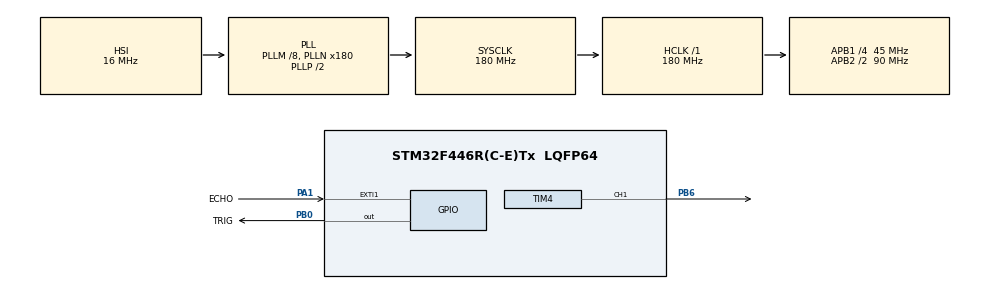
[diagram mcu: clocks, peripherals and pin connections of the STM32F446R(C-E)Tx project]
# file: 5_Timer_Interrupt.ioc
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Mcu.Family=STM32F4
Mcu.Name=STM32F446R(C-E)Tx
Mcu.Package=LQFP64
NVIC.EXTI1_IRQn=true\:0\:0\:false\:false\:true\:true\:true\:true
NVIC.PriorityGroup=NVIC_PRIORITYGROUP_4
NVIC.TIM6_DAC_IRQn=true\:0\:0\:false\:false\:true\:true\:true\:true
PA1.GPIO_Label=ECHO
PA1.GPIO_ModeDefaultEXTI=GPIO_MODE_IT_RISING_FALLING
PA1.Signal=GPXTI1
PB0.GPIO_Label=TRIG
PB0.Signal=GPIO_Output
PB6.Signal=S_TIM4_CH1
ProjectManager.HeapSize=0x200
ProjectManager.StackSize=0x400
ProjectManager.TargetToolchain=STM32CubeIDE
RCC.AHBFreq_Value=180000000
RCC.APB1CLKDivider=RCC_HCLK_DIV4
RCC.APB1Freq_Value=45000000
RCC.APB1TimFreq_Value=90000000
RCC.APB2CLKDivider=RCC_HCLK_DIV2
RCC.APB2Freq_Value=90000000
RCC.APB2TimFreq_Value=180000000
RCC.CortexFreq_Value=180000000
RCC.HCLKFreq_Value=180000000
RCC.PLLM=8
RCC.PLLN=180
RCC.SYSCLKFreq_VALUE=180000000
RCC.SYSCLKSource=RCC_SYSCLKSOURCE_PLLCLK
RCC.USBFreq_Value=180000000
RCC.VCOOutputFreq_Value=360000000
SH.S_TIM4_CH1.0=TIM4_CH1,PWM Generation1 CH1
TIM3.Prescaler=89
TIM4.Channel-PWM\ Generation1\ CH1=TIM_CHANNEL_1
TIM4.Period=999
TIM4.Prescaler=89
TIM6.Period=599
TIM6.Prescaler=8999
VP_TIM3_VS_ClockSourceINT.Mode=Internal
VP_TIM6_VS_ClockSourceINT.Mode=Enable_Timer
board=custom

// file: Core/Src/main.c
/* USER CODE BEGIN Header */
/**
  ******************************************************************************
  * @file           : main.c
  * @brief          : Main program body
  ******************************************************************************
  * @attention
  *
  * Copyright (c) 2026 STMicroelectronics.
  * All rights reserved.
  *
  * This software is licensed under terms that can be found in the LICENSE file
  * in the root directory of this software component.
  * If no LICENSE file comes with this software, it is provided AS-IS.
  *
  ******************************************************************************
  */
/* USER CODE END Header */
#include "main.h"

/* USER CODE BEGIN Includes */
#include "sensor.h"
/* USER CODE END Includes */

/* USER CODE BEGIN PTD */
#define LED_ACTIVE_RANGE_CM 50
#define PWM_MAX_DUTY 999
/* USER CODE END PTD */

TIM_HandleTypeDef htim3;
TIM_HandleTypeDef htim4;
TIM_HandleTypeDef htim6;

void SystemClock_Config(void);
static void MX_GPIO_Init(void);
static void MX_TIM3_Init(void);
static void MX_TIM4_Init(void);
static void MX_TIM6_Init(void);

int main(void)
{

  /* MCU Configuration--------------------------------------------------------*/

  /* Reset of all peripherals, Initializes the Flash interface and the Systick. */
  HAL_Init();

  /* Configure the system clock */
  SystemClock_Config();

  /* Initialize all configured peripherals */
  MX_GPIO_Init();
  MX_TIM3_Init();
  MX_TIM4_Init();
  MX_TIM6_Init();
  /* USER CODE BEGIN 2 */
  Sensor_Init(&htim3, TRIG_GPIO_Port, TRIG_Pin, ECHO_GPIO_Port, ECHO_Pin);
  HAL_TIM_PWM_Start(&htim4, TIM_CHANNEL_1);
  HAL_TIM_Base_Start_IT(&htim6);
  /* USER CODE END 2 */

  /* Infinite loop */
  /* USER CODE BEGIN WHILE */
  while (1)
  {
    uint32_t distance_cm = Sensor_GetDistanceCm();
    uint32_t led_cm = (distance_cm > LED_ACTIVE_RANGE_CM) ? LED_ACTIVE_RANGE_CM : distance_cm;
    uint32_t duty = PWM_MAX_DUTY - ((led_cm - 2) * PWM_MAX_DUTY / (LED_ACTIVE_RANGE_CM - 2));
    __HAL_TIM_SET_COMPARE(&htim4, TIM_CHANNEL_1, duty);
    /* USER CODE END WHILE */

  }
}

void SystemClock_Config(void)
{
  RCC_OscInitTypeDef RCC_OscInitStruct = {0};
  RCC_ClkInitTypeDef RCC_ClkInitStruct = {0};

  /** Configure the main internal regulator output voltage
  */
  __HAL_RCC_PWR_CLK_ENABLE();
  __HAL_PWR_VOLTAGESCALING_CONFIG(PWR_REGULATOR_VOLTAGE_SCALE1);

  /** Initializes the RCC Oscillators according to the specified parameters
  * in the RCC_OscInitTypeDef structure.
  */
  RCC_OscInitStruct.OscillatorType = RCC_OSCILLATORTYPE_HSI;
  RCC_OscInitStruct.HSIState = RCC_HSI_ON;
  RCC_OscInitStruct.HSICalibrationValue = RCC_HSICALIBRATION_DEFAULT;
  RCC_OscInitStruct.PLL.PLLState = RCC_PLL_ON;
  RCC_OscInitStruct.PLL.PLLSource = RCC_PLLSOURCE_HSI;
  RCC_OscInitStruct.PLL.PLLM = 8;
  RCC_OscInitStruct.PLL.PLLN = 180;
  RCC_OscInitStruct.PLL.PLLP = RCC_PLLP_DIV2;
  RCC_OscInitStruct.PLL.PLLQ = 2;
  RCC_OscInitStruct.PLL.PLLR = 2;
  if (HAL_RCC_OscConfig(&RCC_OscInitStruct) != HAL_OK)
  {
    Error_Handler();
  }

  /** Activate the Over-Drive mode
  */
  if (HAL_PWREx_EnableOverDrive() != HAL_OK)
  {
    Error_Handler();
  }

  /** Initializes the CPU, AHB and APB buses clocks
  */
  RCC_ClkInitStruct.ClockType = RCC_CLOCKTYPE_HCLK|RCC_CLOCKTYPE_SYSCLK
                              |RCC_CLOCKTYPE_PCLK1|RCC_CLOCKTYPE_PCLK2;
  RCC_ClkInitStruct.SYSCLKSource = RCC_SYSCLKSOURCE_PLLCLK;
  RCC_ClkInitStruct.AHBCLKDivider = RCC_SYSCLK_DIV1;
  RCC_ClkInitStruct.APB1CLKDivider = RCC_HCLK_DIV4;
  RCC_ClkInitStruct.APB2CLKDivider = RCC_HCLK_DIV2;

  if (HAL_RCC_ClockConfig(&RCC_ClkInitStruct, FLASH_LATENCY_5) != HAL_OK)
  {
    Error_Handler();
  }
}

static void MX_TIM3_Init(void)
{

  TIM_ClockConfigTypeDef sClockSourceConfig = {0};
  TIM_MasterConfigTypeDef sMasterConfig = {0};

  htim3.Instance = TIM3;
  htim3.Init.Prescaler = 89;
  htim3.Init.CounterMode = TIM_COUNTERMODE_UP;
  htim3.Init.Period = 65535;
  htim3.Init.ClockDivision = TIM_CLOCKDIVISION_DIV1;
  htim3.Init.AutoReloadPreload = TIM_AUTORELOAD_PRELOAD_DISABLE;
  if (HAL_TIM_Base_Init(&htim3) != HAL_OK)
  {
    Error_Handler();
  }
  sClockSourceConfig.ClockSource = TIM_CLOCKSOURCE_INTERNAL;
  if (HAL_TIM_ConfigClockSource(&htim3, &sClockSourceConfig) != HAL_OK)
  {
    Error_Handler();
  }
  sMasterConfig.MasterOutputTrigger = TIM_TRGO_RESET;
  sMasterConfig.MasterSlaveMode = TIM_MASTERSLAVEMODE_DISABLE;
  if (HAL_TIMEx_MasterConfigSynchronization(&htim3, &sMasterConfig) != HAL_OK)
  {
    Error_Handler();
  }

}

static void MX_TIM4_Init(void)
{

  TIM_MasterConfigTypeDef sMasterConfig = {0};
  TIM_OC_InitTypeDef sConfigOC = {0};

  htim4.Instance = TIM4;
  htim4.Init.Prescaler = 89;
  htim4.Init.CounterMode = TIM_COUNTERMODE_UP;
  htim4.Init.Period = 999;
  htim4.Init.ClockDivision = TIM_CLOCKDIVISION_DIV1;
  htim4.Init.AutoReloadPreload = TIM_AUTORELOAD_PRELOAD_DISABLE;
  if (HAL_TIM_PWM_Init(&htim4) != HAL_OK)
  {
    Error_Handler();
  }
  sMasterConfig.MasterOutputTrigger = TIM_TRGO_RESET;
  sMasterConfig.MasterSlaveMode = TIM_MASTERSLAVEMODE_DISABLE;
  if (HAL_TIMEx_MasterConfigSynchronization(&htim4, &sMasterConfig) != HAL_OK)
  {
    Error_Handler();
  }
  sConfigOC.OCMode = TIM_OCMODE_PWM1;
  sConfigOC.Pulse = 0;
  sConfigOC.OCPolarity = TIM_OCPOLARITY_HIGH;
  sConfigOC.OCFastMode = TIM_OCFAST_DISABLE;
  if (HAL_TIM_PWM_ConfigChannel(&htim4, &sConfigOC, TIM_CHANNEL_1) != HAL_OK)
  {
    Error_Handler();
  }
  HAL_TIM_MspPostInit(&htim4);

}

static void MX_TIM6_Init(void)
{

  TIM_MasterConfigTypeDef sMasterConfig = {0};

  htim6.Instance = TIM6;
  htim6.Init.Prescaler = 8999;
  htim6.Init.CounterMode = TIM_COUNTERMODE_UP;
  htim6.Init.Period = 599;
  htim6.Init.AutoReloadPreload = TIM_AUTORELOAD_PRELOAD_DISABLE;
  if (HAL_TIM_Base_Init(&htim6) != HAL_OK)
  {
    Error_Handler();
  }
  sMasterConfig.MasterOutputTrigger = TIM_TRGO_RESET;
  sMasterConfig.MasterSlaveMode = TIM_MASTERSLAVEMODE_DISABLE;
  if (HAL_TIMEx_MasterConfigSynchronization(&htim6, &sMasterConfig) != HAL_OK)
  {
    Error_Handler();
  }

}

static void MX_GPIO_Init(void)
{
  GPIO_InitTypeDef GPIO_InitStruct = {0};

  /* GPIO Ports Clock Enable */
  __HAL_RCC_GPIOA_CLK_ENABLE();
  __HAL_RCC_GPIOB_CLK_ENABLE();

  /*Configure GPIO pin Output Level */
  HAL_GPIO_WritePin(TRIG_GPIO_Port, TRIG_Pin, GPIO_PIN_RESET);

  /*Configure GPIO pin : ECHO_Pin */
  GPIO_InitStruct.Pin = ECHO_Pin;
  GPIO_InitStruct.Mode = GPIO_MODE_IT_RISING_FALLING;
  GPIO_InitStruct.Pull = GPIO_NOPULL;
  HAL_GPIO_Init(ECHO_GPIO_Port, &GPIO_InitStruct);

  /*Configure GPIO pin : TRIG_Pin */
  GPIO_InitStruct.Pin = TRIG_Pin;
  GPIO_InitStruct.Mode = GPIO_MODE_OUTPUT_PP;
  GPIO_InitStruct.Pull = GPIO_NOPULL;
  GPIO_InitStruct.Speed = GPIO_SPEED_FREQ_LOW;
  HAL_GPIO_Init(TRIG_GPIO_Port, &GPIO_InitStruct);

  /* EXTI interrupt init*/
  HAL_NVIC_SetPriority(EXTI1_IRQn, 0, 0);
  HAL_NVIC_EnableIRQ(EXTI1_IRQn);

}

/* USER CODE BEGIN 4 */
void HAL_GPIO_EXTI_Callback(uint16_t GPIO_Pin)
{
  Sensor_EXTI_Callback(GPIO_Pin);
}

void HAL_TIM_PeriodElapsedCallback(TIM_HandleTypeDef *htim)
{
  if (htim->Instance == TIM6)
  {
    Sensor_Trigger();
  }
}
/* USER CODE END 4 */

void Error_Handler(void)
{
  __disable_irq();
  while (1)
  {
  }
}
